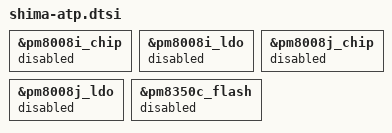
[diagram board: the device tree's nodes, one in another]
#include "shima-idp.dtsi"

&pm8008i_chip {
	status = "disabled";
};

&pm8008i_ldo {
	status = "disabled";
};

&pm8008j_chip {
	status = "disabled";
};

&pm8008j_ldo {
	status = "disabled";
};

&pm8350c_flash {
	status = "disabled";
};
